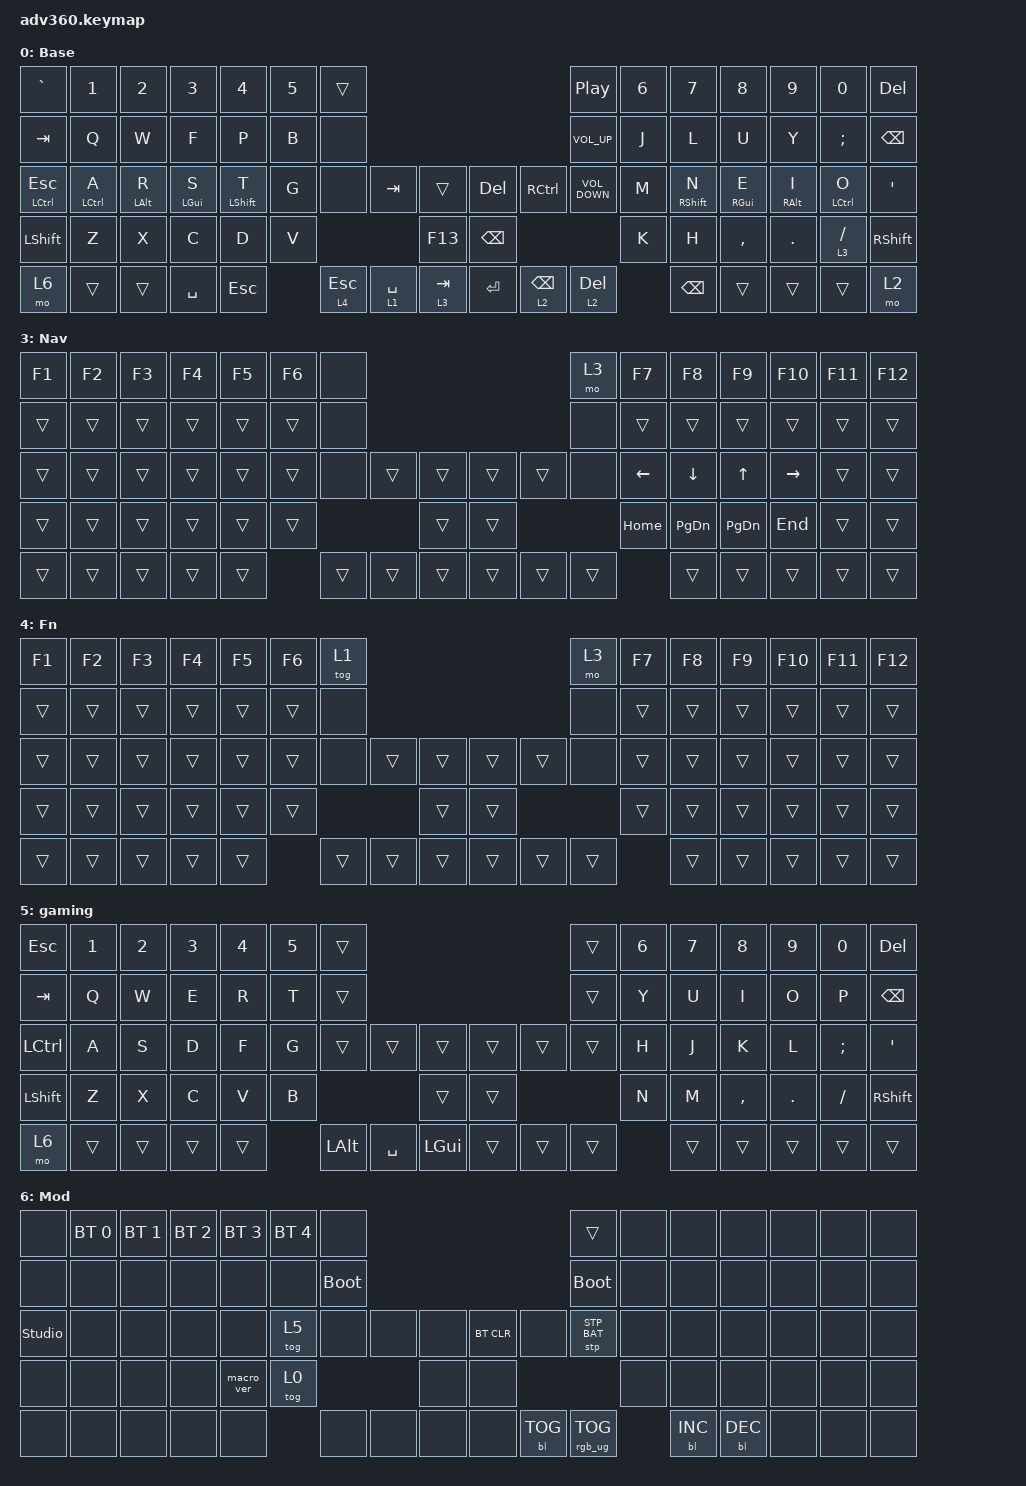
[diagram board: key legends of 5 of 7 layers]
#include <dt-bindings/zmk/stp.h>
#include <behaviors.dtsi>
#include <dt-bindings/zmk/backlight.h>
#include <dt-bindings/zmk/bt.h>
#include <dt-bindings/zmk/keys.h>
#include <dt-bindings/zmk/rgb.h>

/ {
    behaviors {
        #include "macros.dtsi"
      #include "version.dtsi"

        hm: homerow_mods {
            compatible = "zmk,behavior-hold-tap";
            label = "HOMEROW_MODS";
            #binding-cells = <2>;
            tapping-term-ms = <155>;
            quick_tap_ms = <0>;
            flavor = "tap-preferred";
            bindings = <&kp>, <&kp>;
        };

        sk_shift: sk_shift {
            compatible = "zmk,behavior-sticky-key";
            label = "SK_SHIFT";
            bindings = <&sk>;
            #binding-cells = <1>;
            quick-release;
            release-after-ms = <500>;
        };

        caps_word: caps_word {
            compatible = "zmk,behavior-caps-word";
            label = "CAPS_WORD";
            #binding-cells = <0>;
            continue-list = <UNDERSCORE MINUS>;
        };
    };

    combos {
        compatible = "zmk,combos";

        coloncombo {
            bindings = <&kp COLON>;
            key-positions = <25 24>;
        };

        copy {
            bindings = <&kp K_COPY>;
            key-positions = <62 63>;
        };

        paste {
            bindings = <&kp K_PASTE>;
            key-positions = <63 64>;
        };

        capswordshift {
            bindings = <&caps_word>;
            key-positions = <32 41>;
        };

        underscore {
            bindings = <&kp UNDER>;
            key-positions = <55 56>;
        };
    };

    keymap {
        compatible = "zmk,keymap";

        default_layer {
            display-name = "Base";
            bindings = <
&kp GRAVE      &kp N1       &kp N2          &kp N3      &kp N4            &kp N5  &trans                                                                    &kp C_PLAY_PAUSE   &kp N6  &kp N7             &kp N8           &kp N9           &kp N0              &kp DELETE
&kp TAB        &kp Q        &kp W           &kp F       &kp P             &kp B   &none                                                                     &kp C_VOLUME_UP    &kp J   &kp L              &kp U            &kp Y            &kp SEMI            &kp BSPC
&mt LCTRL ESC  &hm LCTRL A  &hm LEFT_ALT R  &hm LGUI S  &hm LEFT_SHIFT T  &kp G   &none         &kp TAB      &trans         &kp DEL        &kp RCTRL        &kp C_VOLUME_DOWN  &kp M   &hm RIGHT_SHIFT N  &hm RIGHT_GUI E  &hm RIGHT_ALT I  &hm LEFT_CONTROL O  &kp APOSTROPHE
&kp LSHFT      &kp Z        &kp X           &kp C       &kp D             &kp V                              &kp F13        &kp BACKSPACE                                      &kp K   &kp H              &kp COMMA        &kp DOT          &lt 3 SLASH         &kp RSHFT
&mo 6          &trans       &trans          &kp SPACE   &kp ESCAPE                &lt 4 ESCAPE  &lt 1 SPACE  &lt 3 TAB      &kp ENTER      &lt 2 BACKSPACE  &lt 2 DELETE               &kp BACKSPACE      &trans           &trans           &trans              &mo 2
            >;
        };

        number {
            display-name = "Number";
            bindings = <
&trans  &trans           &trans        &trans        &trans        &trans       &none                                       &none   &trans        &trans         &trans        &trans                &trans                 &trans
&trans  &kp EXCLAMATION  &kp AT_SIGN   &kp POUND     &kp DOLLAR    &kp PERCENT  &none                                       &none   &kp CARET     &kp AMPERSAND  &kp ASTERISK  &kp LEFT_PARENTHESIS  &kp RIGHT_PARENTHESIS  &trans
&trans  &kp N1           &kp N2        &kp N3        &kp N4        &kp N5       &trans  &trans  &trans      &trans  &trans  &trans  &kp NUMBER_6  &kp N7         &kp N8        &kp N9                &kp N0                 &trans
&trans  &trans           &kp NUMBER_1  &kp NUMBER_2  &kp NUMBER_3  &trans                       &trans      &trans                  &trans        &trans         &trans        &trans                &trans                 &trans
&trans  &trans           &trans        &trans        &trans                     &trans  &trans  &trans      &trans  &trans  &trans                &trans
            >;
        };

        symbol {
            display-name = "Symbol";
            bindings = <
&kp EQUAL  &trans       &trans           &trans     &trans       &trans     &none                                       &none   &trans     &trans          &trans                &trans    &trans            &trans
&trans     &trans       &kp HASH         &kp STAR   &kp PERCENT  &kp EXCL   &none                                       &none   &kp PIPE   &kp PLUS        &kp LEFT_PARENTHESIS  &kp RPAR  &kp LESS_THAN     &trans
&trans     &kp AMPS     &kp AT           &kp STAR   &kp TILDE    &kp GRAVE  &trans  &trans  &trans      &trans  &trans  &trans  &kp MINUS  &kp EQUAL       &kp LBKT              &kp RBKT  &kp GREATER_THAN  &trans
&trans     &kp PERCENT  &kp EXCLAMATION  &kp CARET  &kp DLLR     &kp TILDE                  &trans      &trans                  &kp PLUS   &kp UNDERSCORE  &kp LBRC              &kp RBRC  &kp BACKSLASH     &trans
&trans     &trans       &trans           &trans     &trans                  &trans  &trans  &trans      &trans  &trans  &trans             &kp UNDER
            >;
        };

        nav {
            display-name = "Nav";
            bindings = <
&kp F1  &kp F2  &kp F3  &kp F4  &kp F5  &kp F6  &none                                       &mo 3   &kp F7    &kp F8         &kp F9         &kp F10    &kp F11  &kp F12
&trans  &trans  &trans  &trans  &trans  &trans  &none                                       &none   &trans    &trans         &trans         &trans     &trans   &trans
&trans  &trans  &trans  &trans  &trans  &trans  &none   &trans  &trans      &trans  &trans  &none   &kp LEFT  &kp DOWN       &kp UP         &kp RIGHT  &trans   &trans
&trans  &trans  &trans  &trans  &trans  &trans                  &trans      &trans                  &kp HOME  &kp PAGE_DOWN  &kp PAGE_DOWN  &kp END    &trans   &trans
&trans  &trans  &trans  &trans  &trans          &trans  &trans  &trans      &trans  &trans  &trans            &trans         &trans         &trans     &trans   &trans
            >;
        };

        fn {
            display-name = "Fn";
            bindings = <
&kp F1  &kp F2  &kp F3  &kp F4  &kp F5  &kp F6  &tog 1                                      &mo 3   &kp F7  &kp F8  &kp F9  &kp F10  &kp F11  &kp F12
&trans  &trans  &trans  &trans  &trans  &trans  &none                                       &none   &trans  &trans  &trans  &trans   &trans   &trans
&trans  &trans  &trans  &trans  &trans  &trans  &none   &trans  &trans      &trans  &trans  &none   &trans  &trans  &trans  &trans   &trans   &trans
&trans  &trans  &trans  &trans  &trans  &trans                  &trans      &trans                  &trans  &trans  &trans  &trans   &trans   &trans
&trans  &trans  &trans  &trans  &trans          &trans  &trans  &trans      &trans  &trans  &trans          &trans  &trans  &trans   &trans   &trans
            >;
        };

        gaming {
            bindings = <
&kp ESCAPE  &kp N1  &kp N2  &kp N3  &kp N4  &kp N5  &trans                                                 &trans  &kp N6  &kp N7  &kp N8     &kp N9   &kp N0    &kp DEL
&kp TAB     &kp Q   &kp W   &kp E   &kp R   &kp T   &trans                                                 &trans  &kp Y   &kp U   &kp I      &kp O    &kp P     &kp BSPC
&kp LCTRL   &kp A   &kp S   &kp D   &kp F   &kp G   &trans        &trans     &trans        &trans  &trans  &trans  &kp H   &kp J   &kp K      &kp L    &kp SEMI  &kp APOS
&kp LSHFT   &kp Z   &kp X   &kp C   &kp V   &kp B                            &trans        &trans                  &kp N   &kp M   &kp COMMA  &kp DOT  &kp FSLH  &kp RSHFT
&mo 6       &trans  &trans  &trans  &trans          &kp LEFT_ALT  &kp SPACE  &kp LGUI      &trans  &trans  &trans          &trans  &trans     &trans   &trans    &trans
            >;
        };

        mod {
            display-name = "Mod";
            bindings = <
&none           &bt BT_SEL 0  &bt BT_SEL 1  &bt BT_SEL 2  &bt BT_SEL 3  &bt BT_SEL 4  &none                                                  &trans           &none  &none       &none       &none  &none  &none
&none           &none         &none         &none         &none         &none         &bootloader                                            &bootloader      &none  &none       &none       &none  &none  &none
&studio_unlock  &none         &none         &none         &none         &tog 5        &none        &none  &none      &bt BT_CLR  &none       &stp STP_BAT     &none  &none       &none       &none  &none  &none
&none           &none         &none         &none         &macro_ver    &tog 0                            &none      &none                                    &none  &none       &none       &none  &none  &none
&none           &none         &none         &none         &none                       &none        &none  &none      &none       &bl BL_TOG  &rgb_ug RGB_TOG         &bl BL_INC  &bl BL_DEC  &none  &none  &none
            >;
        };

        extra1 {
            display-name = "Red";
            status = "reserved";
        };

        extra2 {
            display-name = "Purple";
            status = "reserved";
        };

        extra3 {
            display-name = "Cyan";
            status = "reserved";
        };

        extra4 {
            display-name = "Yellow";
            status = "reserved";
        };
    };
};
